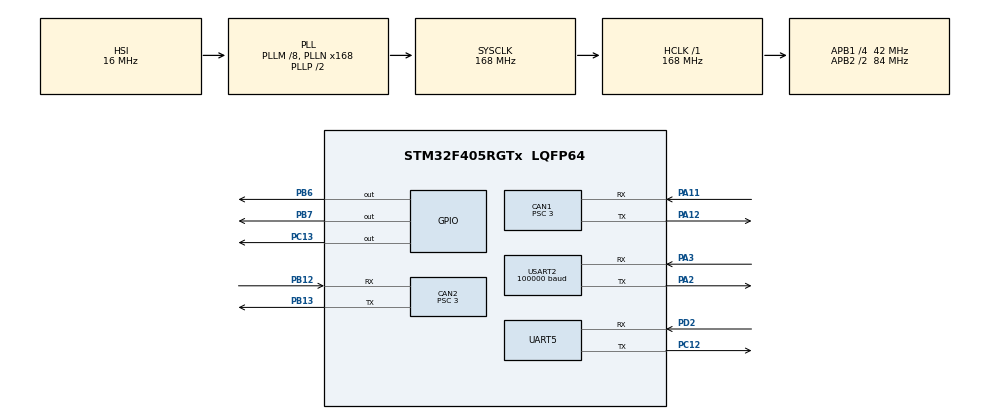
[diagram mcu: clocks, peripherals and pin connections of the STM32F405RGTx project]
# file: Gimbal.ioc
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CAN1.ABOM=ENABLE
CAN1.BS1=CAN_BS1_9TQ
CAN1.BS2=CAN_BS2_4TQ
CAN1.CalculateBaudRate=1000000
CAN1.CalculateTimeBit=1000
CAN1.CalculateTimeQuantum=71.42857142857143
CAN1.NART=ENABLE
CAN1.Prescaler=3
CAN2.ABOM=ENABLE
CAN2.BS1=CAN_BS1_9TQ
CAN2.BS2=CAN_BS2_4TQ
CAN2.CalculateBaudRate=1000000
CAN2.CalculateTimeBit=1000
CAN2.CalculateTimeQuantum=71.42857142857143
CAN2.NART=ENABLE
CAN2.Prescaler=3
Dma.Request0=USART2_RX
Dma.Request1=UART5_TX
Dma.UART5_TX.1.Direction=DMA_MEMORY_TO_PERIPH
Dma.UART5_TX.1.FIFOMode=DMA_FIFOMODE_DISABLE
Dma.UART5_TX.1.Instance=DMA1_Stream7
Dma.UART5_TX.1.MemDataAlignment=DMA_MDATAALIGN_BYTE
Dma.UART5_TX.1.MemInc=DMA_MINC_ENABLE
Dma.UART5_TX.1.Mode=DMA_NORMAL
Dma.UART5_TX.1.PeriphDataAlignment=DMA_PDATAALIGN_BYTE
Dma.UART5_TX.1.PeriphInc=DMA_PINC_DISABLE
Dma.UART5_TX.1.Priority=DMA_PRIORITY_LOW
Dma.USART2_RX.0.Direction=DMA_PERIPH_TO_MEMORY
Dma.USART2_RX.0.FIFOMode=DMA_FIFOMODE_DISABLE
Dma.USART2_RX.0.Instance=DMA1_Stream5
Dma.USART2_RX.0.MemDataAlignment=DMA_MDATAALIGN_BYTE
Dma.USART2_RX.0.MemInc=DMA_MINC_ENABLE
Dma.USART2_RX.0.Mode=DMA_NORMAL
Dma.USART2_RX.0.PeriphDataAlignment=DMA_PDATAALIGN_BYTE
Dma.USART2_RX.0.PeriphInc=DMA_PINC_DISABLE
Dma.USART2_RX.0.Priority=DMA_PRIORITY_VERY_HIGH
FREERTOS.Tasks01=defaultTask,24,128,StartDefaultTask,Default,NULL,Dynamic,NULL,NULL
Mcu.Family=STM32F4
Mcu.Name=STM32F405RGTx
Mcu.Package=LQFP64
NVIC.CAN1_RX0_IRQn=true\:5\:0\:false\:false\:true\:true\:true\:true\:true
NVIC.CAN1_RX1_IRQn=true\:5\:0\:false\:false\:true\:true\:true\:true\:true
NVIC.CAN2_RX0_IRQn=true\:5\:0\:false\:false\:true\:true\:true\:true\:true
NVIC.CAN2_RX1_IRQn=true\:5\:0\:false\:false\:true\:true\:true\:true\:true
NVIC.DMA1_Stream5_IRQn=true\:5\:0\:false\:false\:true\:true\:false\:true\:true
NVIC.DMA1_Stream7_IRQn=true\:5\:0\:false\:false\:true\:true\:false\:true\:true
NVIC.PriorityGroup=NVIC_PRIORITYGROUP_4
NVIC.TIM7_IRQn=true\:15\:0\:false\:false\:true\:false\:false\:true\:true
NVIC.TimeBase=TIM7_IRQn
NVIC.TimeBaseIP=TIM7
NVIC.USART2_IRQn=true\:5\:0\:false\:false\:true\:true\:true\:true\:true
PA11.Mode=CAN_Activate
PA11.Signal=CAN1_RX
PA12.Mode=CAN_Activate
PA12.Signal=CAN1_TX
PA13.Mode=Serial_Wire
PA13.Signal=SYS_JTMS-SWDIO
PA14.Mode=Serial_Wire
PA14.Signal=SYS_JTCK-SWCLK
PA2.Mode=Asynchronous
PA2.Signal=USART2_TX
PA3.Mode=Asynchronous
PA3.Signal=USART2_RX
PB12.Mode=CAN_Activate
PB12.Signal=CAN2_RX
PB13.Mode=CAN_Activate
PB13.Signal=CAN2_TX
PB6.GPIO_ModeDefaultOutputPP=GPIO_MODE_OUTPUT_OD
PB6.GPIO_PuPd=GPIO_PULLUP
PB6.GPIO_Speed=GPIO_SPEED_FREQ_VERY_HIGH
PB6.Signal=GPIO_Output
PB7.GPIO_ModeDefaultOutputPP=GPIO_MODE_OUTPUT_OD
PB7.GPIO_PuPd=GPIO_PULLUP
PB7.GPIO_Speed=GPIO_SPEED_FREQ_VERY_HIGH
PB7.Signal=GPIO_Output
PC12.Mode=Asynchronous
PC12.Signal=UART5_TX
PC13-ANTI_TAMP.GPIO_PuPd=GPIO_PULLUP
PC13-ANTI_TAMP.Signal=GPIO_Output
PD2.Mode=Asynchronous
PD2.Signal=UART5_RX
PH0-OSC_IN.Mode=HSE-External-Oscillator
PH0-OSC_IN.Signal=RCC_OSC_IN
PH1-OSC_OUT.Mode=HSE-External-Oscillator
PH1-OSC_OUT.Signal=RCC_OSC_OUT
ProjectManager.HeapSize=0x200
ProjectManager.StackSize=0x400
ProjectManager.TargetToolchain=MDK-ARM V5.32
RCC.48MHZClocksFreq_Value=84000000
RCC.AHBFreq_Value=168000000
RCC.APB1CLKDivider=RCC_HCLK_DIV4
RCC.APB1Freq_Value=42000000
RCC.APB1TimFreq_Value=84000000
RCC.APB2CLKDivider=RCC_HCLK_DIV2
RCC.APB2Freq_Value=84000000
RCC.APB2TimFreq_Value=168000000
RCC.CortexFreq_Value=168000000
RCC.HCLKFreq_Value=168000000
RCC.HSE_VALUE=25000000
RCC.HSI_VALUE=16000000
RCC.LSE_VALUE=32768
RCC.PLLM=8
RCC.PLLN=168
RCC.SYSCLKFreq_VALUE=168000000
RCC.SYSCLKSource=RCC_SYSCLKSOURCE_PLLCLK
RCC.VCOOutputFreq_Value=336000000
UART5.VirtualMode=Asynchronous
USART2.BaudRate=100000
USART2.Mode=MODE_RX
USART2.Parity=PARITY_EVEN
USART2.VirtualMode=VM_ASYNC
USART2.WordLength=WORDLENGTH_9B
VP_FREERTOS_VS_CMSIS_V2.Mode=CMSIS_V2
VP_SYS_VS_tim7.Mode=TIM7
board=custom

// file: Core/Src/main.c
/* USER CODE BEGIN Header */
/**
  ******************************************************************************
  * @file           : main.c
  * @brief          : Main program body
  ******************************************************************************
  * @attention
  *
  * Copyright (c) 2024 STMicroelectronics.
  * All rights reserved.
  *
  * This software is licensed under terms that can be found in the LICENSE file
  * in the root directory of this software component.
  * If no LICENSE file comes with this software, it is provided AS-IS.
  *
  ******************************************************************************
  */
/* USER CODE END Header */
#include "main.h"
#include "cmsis_os.h"
#include "can.h"
#include "dma.h"
#include "usart.h"
#include "gpio.h"

/* USER CODE BEGIN Includes */
#include "string.h"
/* USER CODE END Includes */

void SystemClock_Config(void);
void MX_FREERTOS_Init(void);

int main(void)
{

  /* MCU Configuration--------------------------------------------------------*/

  /* Reset of all peripherals, Initializes the Flash interface and the Systick. */
  HAL_Init();

  /* Configure the system clock */
  SystemClock_Config();

  /* Initialize all configured peripherals */
  MX_GPIO_Init();
  MX_DMA_Init();
  MX_CAN1_Init();
  MX_CAN2_Init();
  MX_USART2_UART_Init();
  MX_UART5_Init();

  /* Init scheduler */
  osKernelInitialize();  /* Call init function for freertos objects (in freertos.c) */
  MX_FREERTOS_Init();

  /* Start scheduler */
  osKernelStart();
  /* We should never get here as control is now taken by the scheduler */
  /* Infinite loop */
  while (1)
  {

  }
}

void SystemClock_Config(void)
{
  RCC_OscInitTypeDef RCC_OscInitStruct = {0};
  RCC_ClkInitTypeDef RCC_ClkInitStruct = {0};

  /** Configure the main internal regulator output voltage
  */
  __HAL_RCC_PWR_CLK_ENABLE();
  __HAL_PWR_VOLTAGESCALING_CONFIG(PWR_REGULATOR_VOLTAGE_SCALE1);

  /** Initializes the RCC Oscillators according to the specified parameters
  * in the RCC_OscInitTypeDef structure.
  */
  RCC_OscInitStruct.OscillatorType = RCC_OSCILLATORTYPE_HSI;
  RCC_OscInitStruct.HSIState = RCC_HSI_ON;
  RCC_OscInitStruct.HSICalibrationValue = RCC_HSICALIBRATION_DEFAULT;
  RCC_OscInitStruct.PLL.PLLState = RCC_PLL_ON;
  RCC_OscInitStruct.PLL.PLLSource = RCC_PLLSOURCE_HSI;
  RCC_OscInitStruct.PLL.PLLM = 8;
  RCC_OscInitStruct.PLL.PLLN = 168;
  RCC_OscInitStruct.PLL.PLLP = RCC_PLLP_DIV2;
  RCC_OscInitStruct.PLL.PLLQ = 4;
  if (HAL_RCC_OscConfig(&RCC_OscInitStruct) != HAL_OK)
  {
    Error_Handler();
  }

  /** Initializes the CPU, AHB and APB buses clocks
  */
  RCC_ClkInitStruct.ClockType = RCC_CLOCKTYPE_HCLK|RCC_CLOCKTYPE_SYSCLK
                              |RCC_CLOCKTYPE_PCLK1|RCC_CLOCKTYPE_PCLK2;
  RCC_ClkInitStruct.SYSCLKSource = RCC_SYSCLKSOURCE_PLLCLK;
  RCC_ClkInitStruct.AHBCLKDivider = RCC_SYSCLK_DIV1;
  RCC_ClkInitStruct.APB1CLKDivider = RCC_HCLK_DIV4;
  RCC_ClkInitStruct.APB2CLKDivider = RCC_HCLK_DIV2;

  if (HAL_RCC_ClockConfig(&RCC_ClkInitStruct, FLASH_LATENCY_5) != HAL_OK)
  {
    Error_Handler();
  }
}

void HAL_TIM_PeriodElapsedCallback(TIM_HandleTypeDef *htim)
{
  if (htim->Instance == TIM7) {
    HAL_IncTick();
  }
}

void Error_Handler(void)
{
  __disable_irq();
  while (1)
  {
  }
}

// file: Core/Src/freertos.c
/* USER CODE BEGIN Header */
/**
 ******************************************************************************
 * File Name          : freertos.c
 * Description        : Code for freertos applications
 ******************************************************************************
 * @attention
 *
 * Copyright (c) 2024 STMicroelectronics.
 * All rights reserved.
 *
 * This software is licensed under terms that can be found in the LICENSE file
 * in the root directory of this software component.
 * If no LICENSE file comes with this software, it is provided AS-IS.
 *
 ******************************************************************************
 */
/* USER CODE END Header */

#include "FreeRTOS.h"
#include "task.h"
#include "main.h"
#include "cmsis_os.h"

/* USER CODE BEGIN Includes */
#include "UserMain.h"
#include "gpio.h"
/* USER CODE END Includes */

/* Definitions for defaultTask */
osThreadId_t defaultTaskHandle;
const osThreadAttr_t defaultTask_attributes = {
  .name = "defaultTask",
  .stack_size = 128 * 4,
  .priority = (osPriority_t) osPriorityNormal,
};

void StartDefaultTask(void *argument);

void MX_FREERTOS_Init(void); /* (MISRA C 2004 rule 8.1) */

void MX_FREERTOS_Init(void) {

  /* Create the thread(s) */
  /* creation of defaultTask */
  defaultTaskHandle = osThreadNew(StartDefaultTask, NULL, &defaultTask_attributes);

}

void StartDefaultTask(void *argument)
{
  /* USER CODE BEGIN StartDefaultTask */
  System_Tasks_Init();
  vTaskDelete(NULL);
  /* Infinite loop */
  for (;;)
  {
    // HAL_GPIO_TogglePin(GPIOC,GPIO_PIN_13);
    osDelay(1);
  }
  /* USER CODE END StartDefaultTask */
}
